VERSION ""

NS_ :

BS_:

BU_: Headless Tractor_Controller Steering_Module

BO_ 3221225472 VECTOR__INDEPENDENT_SIG_MSG: 0 Vector__XXX
 SG_ NewSignal_0008 : 56|8@1+ (1,0) [0|0] "" Vector__XXX

BO_ 2348876545 Trans_Control_1: 8 Headless
 SG_ MP1_Displacement : 0|16@1+ (1,-10000) [-10000|10000] "" Vector__XXX
 SG_ MP2_Displacement : 16|16@1+ (1,-10000) [-10000|10000] "" Vector__XXX

BO_ 2348876289 Test_Stand_Control_1: 8 Headless
 SG_ Swash_Command : 0|16@1+ (1,-10000) [-10000|10000] "" Vector__XXX
 SG_ Pressure_Command : 16|16@1+ (1,0) [0|4000] "" Vector__XXX

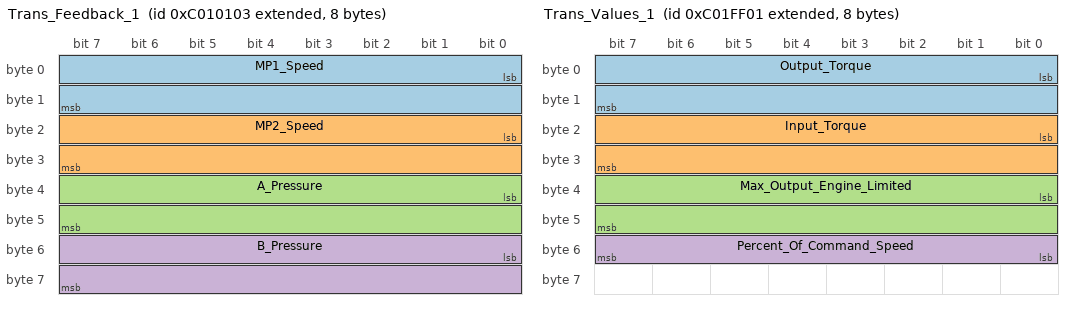
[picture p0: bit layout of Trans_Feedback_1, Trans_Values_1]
BO_ 2348876035 Trans_Feedback_1: 8 Tractor_Controller
 SG_ MP1_Speed : 0|16@1+ (1,0) [0|4500] "" Vector__XXX
 SG_ MP2_Speed : 16|16@1+ (1,0) [0|4500] "" Vector__XXX
 SG_ A_Pressure : 32|16@1+ (1,0) [0|4500] "" Vector__XXX
 SG_ B_Pressure : 48|16@1+ (1,0) [0|4500] "" Vector__XXX

BO_ 2348941571 Trans_Feedback_2: 8 Tractor_Controller
 SG_ MP1_Actual_Displacement : 0|16@1+ (1,-10000) [-10000|10000] "" Vector__XXX
 SG_ MP2_Actual_Displacement : 16|16@1+ (1,-10000) [-10000|10000] "" Vector__XXX

BO_ 2348941057 Trans_Values_1: 8 Headless
 SG_ Output_Torque : 0|16@1+ (1,0) [0|4800] "inlbs" Vector__XXX
 SG_ Input_Torque : 16|16@1+ (1,0) [0|500] "inlbs" Vector__XXX
 SG_ Max_Output_Engine_Limited : 32|16@1+ (1,0) [0|2000] "rpm" Vector__XXX
 SG_ Percent_Of_Command_Speed : 48|8@1+ (1,0) [0|200] "%" Vector__XXX

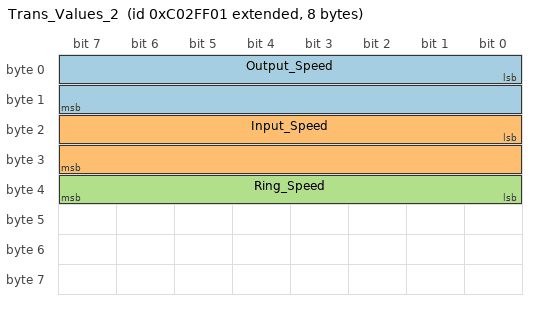
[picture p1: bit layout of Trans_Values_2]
BO_ 2349006593 Trans_Values_2: 8 Headless
 SG_ Output_Speed : 0|16@1+ (1,0) [0|2000] "rpm" Vector__XXX
 SG_ Input_Speed : 16|16@1+ (1,0) [0|5000] "rpm" Vector__XXX
 SG_ Ring_Speed : 32|8@1+ (1,0) [0|0] "" Vector__XXX

BO_ 2348941060 Steering_Module: 8 Steering_Module
 SG_ Steering_Position_Command : 0|16@1+ (1,10000) [-10000|10000] "" Vector__XXX

BO_ 2349007875 Steering_Feedback: 8 Tractor_Controller
 SG_ Resistance : 0|16@1+ (1,10000) [-10000|10000] "" Vector__XXX
